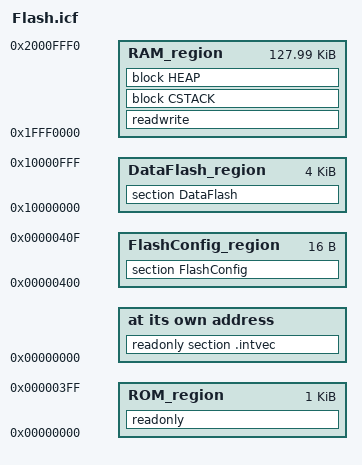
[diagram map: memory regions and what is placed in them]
/*###ICF### Section handled by ICF editor, don't touch! ****/
/*-Editor annotation file-*/
/* IcfEditorFile="$TOOLKIT_DIR$\config\ide\IcfEditor\a_v1_0.xml" */
/*-Specials-*/
define symbol __ICFEDIT_intvec_start__ = 0x00000000;
/*-Memory Regions-*/
define symbol __ICFEDIT_region_ROM_start__   = 0x00000000;
define symbol __ICFEDIT_region_ROM_end__     = 0x0007FFFF;
define symbol __ICFEDIT_region_RAM_start__   = 0x1fff0000;
define symbol __ICFEDIT_region_RAM_end__     = 0x2000FFF0;
/*-Sizes-*/
define symbol __ICFEDIT_size_cstack__   = 0x1000;
define symbol __ICFEDIT_size_heap__     = 0x4000;
/**** End of ICF editor section. ###ICF###*/

define symbol DataFlash_start__  = 0x10000000;
define symbol DataFlash_end__    = 0x10000fff;

define symbol FlashConfig_start__= 0x00000400;
define symbol FlashConfig_end__  = 0x0000040f;

define memory mem with size = 4G;
define region ROM_region   = mem:[from __ICFEDIT_region_ROM_start__ to (FlashConfig_start__ - 1)] | [from (FlashConfig_end__+1)  to __ICFEDIT_region_ROM_end__];
define region RAM_region   = mem:[from __ICFEDIT_region_RAM_start__   to __ICFEDIT_region_RAM_end__];

define block CSTACK    with alignment = 8, size = __ICFEDIT_size_cstack__   { };
define block HEAP      with alignment = 8, size = __ICFEDIT_size_heap__     { };

define region DataFlash_region   = mem:[from DataFlash_start__ to DataFlash_end__];
define region FlashConfig_region = mem:[from FlashConfig_start__ to FlashConfig_end__];

initialize by copy { readwrite };
do not initialize  { section .noinit };

place at address mem:__ICFEDIT_intvec_start__ { readonly section .intvec };

place in ROM_region   { readonly };
place in RAM_region   { readwrite, block CSTACK, block HEAP };

place in DataFlash_region {section DataFlash};

place in FlashConfig_region {section FlashConfig};
